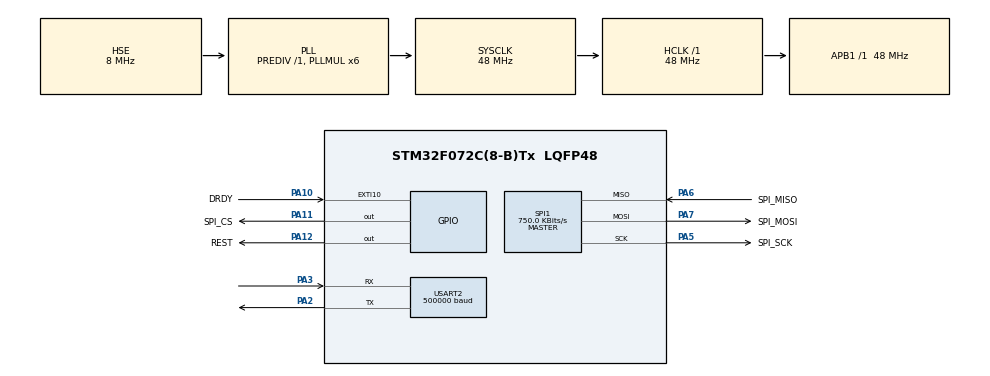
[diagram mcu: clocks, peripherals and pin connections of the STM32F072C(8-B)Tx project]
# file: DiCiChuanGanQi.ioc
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Dma.Request0=USART2_TX
Dma.USART2_TX.0.Direction=DMA_MEMORY_TO_PERIPH
Dma.USART2_TX.0.Instance=DMA1_Channel4
Dma.USART2_TX.0.MemDataAlignment=DMA_MDATAALIGN_BYTE
Dma.USART2_TX.0.MemInc=DMA_MINC_ENABLE
Dma.USART2_TX.0.Mode=DMA_NORMAL
Dma.USART2_TX.0.PeriphDataAlignment=DMA_PDATAALIGN_BYTE
Dma.USART2_TX.0.PeriphInc=DMA_PINC_DISABLE
Dma.USART2_TX.0.Priority=DMA_PRIORITY_LOW
Mcu.Family=STM32F0
Mcu.Name=STM32F072C(8-B)Tx
Mcu.Package=LQFP48
NVIC.DMA1_Channel4_5_6_7_IRQn=true\:0\:0\:false\:false\:true\:false\:true
NVIC.EXTI4_15_IRQn=true\:1\:0\:true\:false\:true\:true\:true
NVIC.USART2_IRQn=true\:0\:0\:false\:false\:true\:true\:true
PA10.GPIO_Label=DRDY
PA10.GPIO_ModeDefaultEXTI=GPIO_MODE_IT_FALLING
PA10.GPIO_PuPd=GPIO_PULLUP
PA10.Signal=GPXTI10
PA11.GPIO_Label=SPI_CS
PA11.GPIO_PuPd=GPIO_PULLUP
PA11.GPIO_Speed=GPIO_SPEED_FREQ_MEDIUM
PA11.PinState=GPIO_PIN_SET
PA11.Signal=GPIO_Output
PA12.GPIO_Label=REST
PA12.GPIO_PuPd=GPIO_PULLUP
PA12.PinState=GPIO_PIN_SET
PA12.Signal=GPIO_Output
PA13.Mode=Serial_Wire
PA13.Signal=SYS_SWDIO
PA14.Mode=Serial_Wire
PA14.Signal=SYS_SWCLK
PA2.Mode=Asynchronous
PA2.Signal=USART2_TX
PA3.Mode=Asynchronous
PA3.Signal=USART2_RX
PA5.GPIO_Label=SPI_SCK
PA5.Mode=Full_Duplex_Master
PA5.Signal=SPI1_SCK
PA6.GPIO_Label=SPI_MISO
PA6.Mode=Full_Duplex_Master
PA6.Signal=SPI1_MISO
PA7.GPIO_Label=SPI_MOSI
PA7.Mode=Full_Duplex_Master
PA7.Signal=SPI1_MOSI
PF0-OSC_IN.Mode=HSE-External-Oscillator
PF0-OSC_IN.Signal=RCC_OSC_IN
PF1-OSC_OUT.Mode=HSE-External-Oscillator
PF1-OSC_OUT.Signal=RCC_OSC_OUT
ProjectManager.HeapSize=0x200
ProjectManager.StackSize=0x400
ProjectManager.TargetToolchain=MDK-ARM V5.27
RCC.AHBFreq_Value=48000000
RCC.APB1Freq_Value=48000000
RCC.APB1TimFreq_Value=48000000
RCC.HCLKFreq_Value=48000000
RCC.PLLMUL=RCC_PLL_MUL6
RCC.PLLSourceVirtual=RCC_PLLSOURCE_HSE
RCC.SYSCLKFreq_VALUE=48000000
RCC.SYSCLKSource=RCC_SYSCLKSOURCE_PLLCLK
SPI1.BaudRatePrescaler=SPI_BAUDRATEPRESCALER_64
SPI1.CLKPhase=SPI_PHASE_2EDGE
SPI1.CalculateBaudRate=750.0 KBits/s
SPI1.DataSize=SPI_DATASIZE_8BIT
SPI1.Direction=SPI_DIRECTION_2LINES
SPI1.Mode=SPI_MODE_MASTER
SPI1.VirtualType=VM_MASTER
USART2.BaudRate=500000
USART2.VirtualMode-Asynchronous=VM_ASYNC
VP_IWDG_VS_IWDG.Mode=IWDG_Activate
board=custom

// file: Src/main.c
/* USER CODE BEGIN Header */
/**
  ******************************************************************************
  * @file           : main.c
  * @brief          : Main program body
  ******************************************************************************
  * @attention
  *
  * <h2><center>&copy; Copyright (c) 2020 STMicroelectronics.
  * All rights reserved.</center></h2>
  *
  * This software component is licensed by ST under BSD 3-Clause license,
  * the "License"; You may not use this file except in compliance with the
  * License. You may obtain a copy of the License at:
  *                        opensource.org/licenses/BSD-3-Clause
  *
  ******************************************************************************
  */
/* USER CODE END Header */
#include "main.h"
#include "dma.h"
#include "iwdg.h"
#include "spi.h"
#include "usart.h"
#include "gpio.h"

/* USER CODE BEGIN Includes */
#include "..\vsDCCGQ\ADS131M06.h"
/* USER CODE END Includes */

void SystemClock_Config(void);

int main(void)
{
  /* USER CODE BEGIN 1 */
	uint8_t i,tx[20];
  /* USER CODE END 1 */

  /* MCU Configuration--------------------------------------------------------*/

  /* Reset of all peripherals, Initializes the Flash interface and the Systick. */
  HAL_Init();

  /* Configure the system clock */
  SystemClock_Config();

  /* Initialize all configured peripherals */
  MX_GPIO_Init();
  MX_DMA_Init();
  //MX_IWDG_Init();
  MX_SPI1_Init();
  MX_USART2_UART_Init();
  /* USER CODE BEGIN 2 */

  SPS = 500;
  ADS131_Init();
  __HAL_GPIO_EXTI_CLEAR_IT(GPIO_PIN_10);
  HAL_NVIC_EnableIRQ(EXTI4_15_IRQn);

  while (HAL_UART_Receive_IT(&huart2, &huart2Rx, 1) == HAL_OK);
  /* USER CODE END 2 */

  /* Infinite loop */
  while (1)
  {

  }
}

void SystemClock_Config(void)
{
  RCC_OscInitTypeDef RCC_OscInitStruct = {0};
  RCC_ClkInitTypeDef RCC_ClkInitStruct = {0};
  RCC_PeriphCLKInitTypeDef PeriphClkInit = {0};

  /** Initializes the RCC Oscillators according to the specified parameters
  * in the RCC_OscInitTypeDef structure.
  */
  RCC_OscInitStruct.OscillatorType = RCC_OSCILLATORTYPE_LSI|RCC_OSCILLATORTYPE_HSE;
  RCC_OscInitStruct.HSEState = RCC_HSE_ON;
  RCC_OscInitStruct.LSIState = RCC_LSI_ON;
  RCC_OscInitStruct.PLL.PLLState = RCC_PLL_ON;
  RCC_OscInitStruct.PLL.PLLSource = RCC_PLLSOURCE_HSE;
  RCC_OscInitStruct.PLL.PLLMUL = RCC_PLL_MUL6;
  RCC_OscInitStruct.PLL.PREDIV = RCC_PREDIV_DIV1;
  if (HAL_RCC_OscConfig(&RCC_OscInitStruct) != HAL_OK)
  {
    Error_Handler();
  }
  /** Initializes the CPU, AHB and APB buses clocks
  */
  RCC_ClkInitStruct.ClockType = RCC_CLOCKTYPE_HCLK|RCC_CLOCKTYPE_SYSCLK
                              |RCC_CLOCKTYPE_PCLK1;
  RCC_ClkInitStruct.SYSCLKSource = RCC_SYSCLKSOURCE_PLLCLK;
  RCC_ClkInitStruct.AHBCLKDivider = RCC_SYSCLK_DIV1;
  RCC_ClkInitStruct.APB1CLKDivider = RCC_HCLK_DIV1;

  if (HAL_RCC_ClockConfig(&RCC_ClkInitStruct, FLASH_LATENCY_1) != HAL_OK)
  {
    Error_Handler();
  }
  PeriphClkInit.PeriphClockSelection = RCC_PERIPHCLK_USART2;
  PeriphClkInit.Usart2ClockSelection = RCC_USART2CLKSOURCE_PCLK1;
  if (HAL_RCCEx_PeriphCLKConfig(&PeriphClkInit) != HAL_OK)
  {
    Error_Handler();
  }
}

void Error_Handler(void)
{
}

/************************ (C) COPYRIGHT STMicroelectronics *****END OF FILE****/
